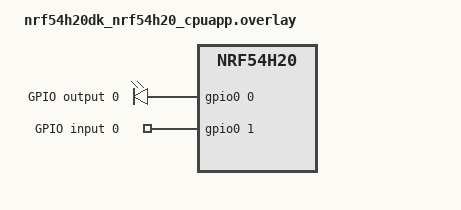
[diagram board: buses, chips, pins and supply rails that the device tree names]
/ {
	aliases {
		led = &led0;
		/delete-property/ led1;
		out0 = &output0;
		in0 = &input0;
	};

	outputs {
		compatible = "gpio-leds";

		output0: output_0 {
			gpios = <&gpio0 0 GPIO_ACTIVE_HIGH>;
			label = "GPIO output 0";
		};
	};

	inputs {
		compatible = "gpio-keys";

		input0: input_0 {
			gpios = <&gpio0 1 GPIO_ACTIVE_HIGH>;
			label = "GPIO input 0";
		};
	};
};

/delete-node/ &led1;

&gpiote130 {
	status = "okay";
	owned-channels = <0>;
};
